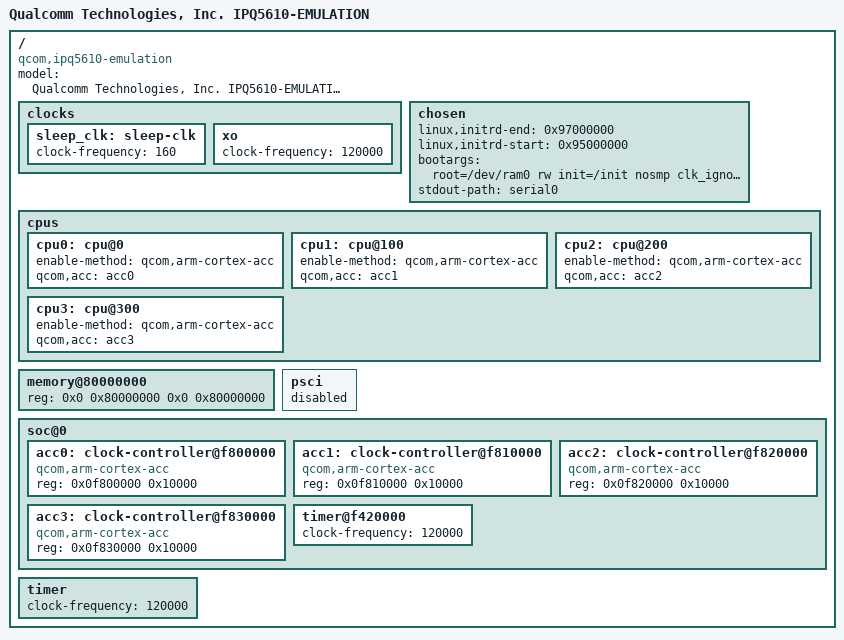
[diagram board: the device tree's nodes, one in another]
// SPDX-License-Identifier: (GPL-2.0+ OR BSD-3-Clause)
/*
 * IPQ5610 Emulation board device tree source
 *
 * Copyright (c) 2020-2021 The Linux Foundation. All rights reserved.
 * Copyright (c) Qualcomm Technologies, Inc. and/or its subsidiaries.
 */

/dts-v1/;

#include "ipq5610.dtsi"

/ {
	model = "Qualcomm Technologies, Inc. IPQ5610-EMULATION";
	compatible = "qcom,ipq5610-emulation", "qcom,ipq5610";

	/* Timer freq for rumi = timer freq / 200 */
	clocks {
		/* sleep-clk freq for rumi = sleep-clk freq (32000) / 200 */
		sleep_clk: sleep-clk {
			clock-frequency = <160>;
		};

		/* xo freq for rumi = xo freq (24000000) / 200 */
		xo: xo {
			clock-frequency = <120000>;
		};
	};

	chosen {
		linux,initrd-end = <0x97000000>;
		linux,initrd-start = <0x95000000>;
		bootargs = "root=/dev/ram0 rw init=/init nosmp clk_ignore_unused";
		stdout-path = "serial0";
	};

	cpus: cpus {
		cpu0: cpu@0 {
			enable-method = "qcom,arm-cortex-acc";
			qcom,acc = <&acc0>;
		};

		cpu1: cpu@100 {
			enable-method = "qcom,arm-cortex-acc";
			qcom,acc = <&acc1>;
		};

		cpu2: cpu@200 {
			enable-method = "qcom,arm-cortex-acc";
			qcom,acc = <&acc2>;
		};

		cpu3: cpu@300 {
			enable-method = "qcom,arm-cortex-acc";
			qcom,acc = <&acc3>;
		};
	};

	memory@80000000 {
		reg = <0x0 0x80000000 0x0 0x80000000>;
	};

	psci {
		status = "disabled";
	};

	soc@0 {
		acc0: clock-controller@f800000 {
			compatible = "qcom,arm-cortex-acc";
			reg = <0x0f800000 0x10000>;
		};

		acc1: clock-controller@f810000 {
			compatible = "qcom,arm-cortex-acc";
			reg = <0x0f810000 0x10000>;
		};

		acc2: clock-controller@f820000 {
			compatible = "qcom,arm-cortex-acc";
			reg = <0x0f820000 0x10000>;
		};

		acc3: clock-controller@f830000 {
			compatible = "qcom,arm-cortex-acc";
			reg = <0x0f830000 0x10000>;
		};

		/* Timer freq for rumi = timer freq (24000000) / 200 */
		timer@f420000 {
			clock-frequency = <120000>;
		};
	};

	/* Timer freq for rumi = timer freq (24000000) / 200 */
	timer {
		clock-frequency = <120000>;
	};
};

